VERSION "teryx"

NS_ :

BS_:

BU_: PI_DASH PICO_BOX SHINEGLE BENCH

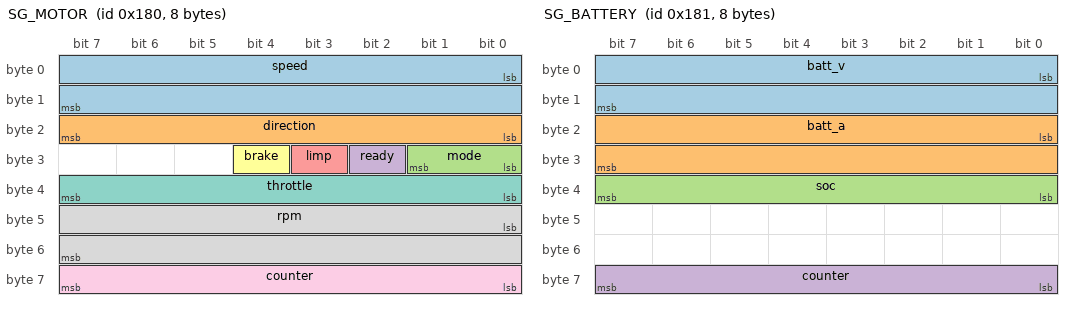
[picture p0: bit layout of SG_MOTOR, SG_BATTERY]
BO_ 384 SG_MOTOR: 8 SHINEGLE
 SG_ speed : 0|16@1+ (0.1,0) [0|6553.5] "km/h" Vector__XXX
 SG_ direction : 16|8@1+ (1,0) [0|255] "" Vector__XXX
 SG_ mode : 24|2@1+ (1,0) [0|3] "" Vector__XXX
 SG_ ready : 26|1@1+ (1,0) [0|1] "" Vector__XXX
 SG_ limp : 27|1@1+ (1,0) [0|1] "" Vector__XXX
 SG_ brake : 28|1@1+ (1,0) [0|1] "" Vector__XXX
 SG_ throttle : 32|8@1+ (1,0) [0|255] "%" Vector__XXX
 SG_ rpm : 40|16@1- (1,0) [-32768|32767] "rpm" Vector__XXX
 SG_ counter : 56|8@1+ (1,0) [0|255] "" Vector__XXX

BO_ 385 SG_BATTERY: 8 SHINEGLE
 SG_ batt_v : 0|16@1+ (0.1,0) [0|6553.5] "V" Vector__XXX
 SG_ batt_a : 16|16@1- (0.1,0) [-3276.8|3276.7] "A" Vector__XXX
 SG_ soc : 32|8@1+ (1,0) [0|255] "%" Vector__XXX
 SG_ counter : 56|8@1+ (1,0) [0|255] "" Vector__XXX

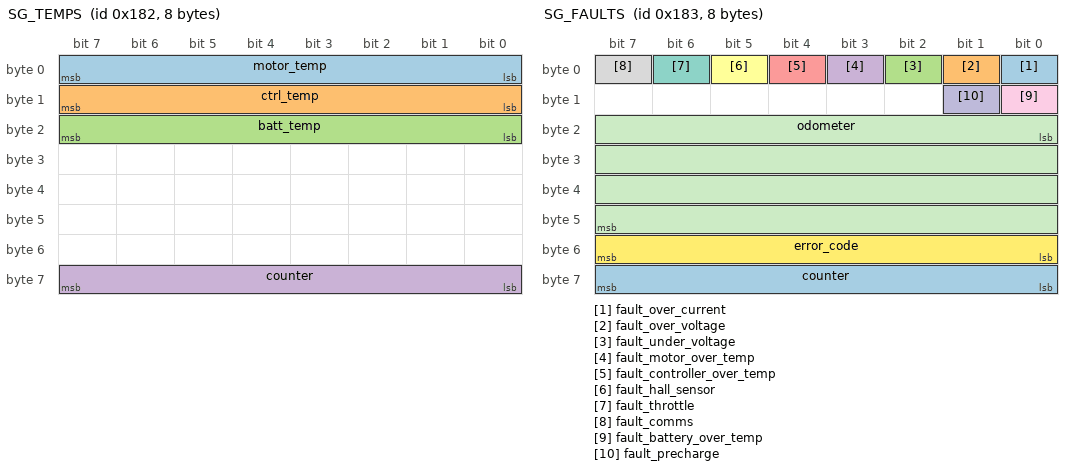
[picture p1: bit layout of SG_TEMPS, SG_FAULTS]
BO_ 386 SG_TEMPS: 8 SHINEGLE
 SG_ motor_temp : 0|8@1+ (1,-40) [-40|215] "C" Vector__XXX
 SG_ ctrl_temp : 8|8@1+ (1,-40) [-40|215] "C" Vector__XXX
 SG_ batt_temp : 16|8@1+ (1,-40) [-40|215] "C" Vector__XXX
 SG_ counter : 56|8@1+ (1,0) [0|255] "" Vector__XXX

BO_ 387 SG_FAULTS: 8 SHINEGLE
 SG_ fault_over_current : 0|1@1+ (1,0) [0|1] "" Vector__XXX
 SG_ fault_over_voltage : 1|1@1+ (1,0) [0|1] "" Vector__XXX
 SG_ fault_under_voltage : 2|1@1+ (1,0) [0|1] "" Vector__XXX
 SG_ fault_motor_over_temp : 3|1@1+ (1,0) [0|1] "" Vector__XXX
 SG_ fault_controller_over_temp : 4|1@1+ (1,0) [0|1] "" Vector__XXX
 SG_ fault_hall_sensor : 5|1@1+ (1,0) [0|1] "" Vector__XXX
 SG_ fault_throttle : 6|1@1+ (1,0) [0|1] "" Vector__XXX
 SG_ fault_comms : 7|1@1+ (1,0) [0|1] "" Vector__XXX
 SG_ fault_battery_over_temp : 8|1@1+ (1,0) [0|1] "" Vector__XXX
 SG_ fault_precharge : 9|1@1+ (1,0) [0|1] "" Vector__XXX
 SG_ odometer : 16|32@1+ (0.1,0) [0|4.29497e+08] "km" Vector__XXX
 SG_ error_code : 48|8@1+ (1,0) [0|255] "" Vector__XXX
 SG_ counter : 56|8@1+ (1,0) [0|255] "" Vector__XXX

BO_ 1792 PI_HEARTBEAT: 8 PI_DASH
 SG_ counter : 0|8@1+ (1,0) [0|255] "" Vector__XXX
 SG_ dash_state : 8|8@1+ (1,0) [0|255] "" Vector__XXX

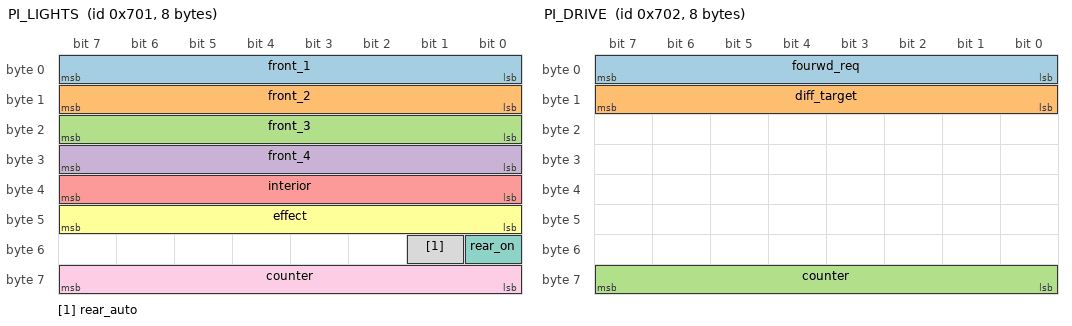
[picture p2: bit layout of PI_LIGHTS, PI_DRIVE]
BO_ 1793 PI_LIGHTS: 8 PI_DASH
 SG_ front_1 : 0|8@1+ (1,0) [0|255] "" Vector__XXX
 SG_ front_2 : 8|8@1+ (1,0) [0|255] "" Vector__XXX
 SG_ front_3 : 16|8@1+ (1,0) [0|255] "" Vector__XXX
 SG_ front_4 : 24|8@1+ (1,0) [0|255] "" Vector__XXX
 SG_ interior : 32|8@1+ (1,0) [0|255] "" Vector__XXX
 SG_ effect : 40|8@1+ (1,0) [0|255] "" Vector__XXX
 SG_ rear_on : 48|1@1+ (1,0) [0|1] "" Vector__XXX
 SG_ rear_auto : 49|1@1+ (1,0) [0|1] "" Vector__XXX
 SG_ counter : 56|8@1+ (1,0) [0|255] "" Vector__XXX

BO_ 1794 PI_DRIVE: 8 PI_DASH
 SG_ fourwd_req : 0|8@1+ (1,0) [0|255] "" Vector__XXX
 SG_ diff_target : 8|8@1+ (1,0) [0|255] "%" Vector__XXX
 SG_ counter : 56|8@1+ (1,0) [0|255] "" Vector__XXX

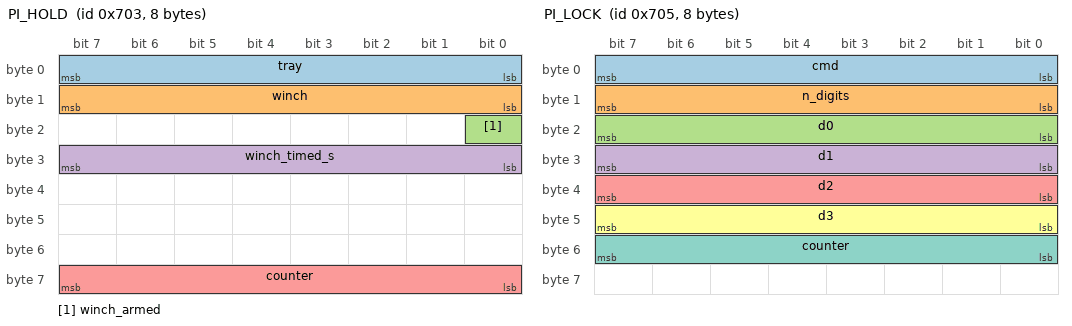
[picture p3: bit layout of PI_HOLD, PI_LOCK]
BO_ 1795 PI_HOLD: 8 PI_DASH
 SG_ tray : 0|8@1- (1,0) [-128|127] "" Vector__XXX
 SG_ winch : 8|8@1- (1,0) [-128|127] "" Vector__XXX
 SG_ winch_armed : 16|1@1+ (1,0) [0|1] "" Vector__XXX
 SG_ winch_timed_s : 24|8@1+ (1,0) [0|255] "s" Vector__XXX
 SG_ counter : 56|8@1+ (1,0) [0|255] "" Vector__XXX

BO_ 1796 PI_SETTINGS: 8 PI_DASH
 SG_ key : 0|8@1+ (1,0) [0|255] "" Vector__XXX
 SG_ value : 16|16@1+ (1,0) [0|65535] "" Vector__XXX

BO_ 1797 PI_LOCK: 8 PI_DASH
 SG_ cmd : 0|8@1+ (1,0) [0|255] "" Vector__XXX
 SG_ n_digits : 8|8@1+ (1,0) [0|255] "" Vector__XXX
 SG_ d0 : 16|8@1+ (1,0) [0|255] "" Vector__XXX
 SG_ d1 : 24|8@1+ (1,0) [0|255] "" Vector__XXX
 SG_ d2 : 32|8@1+ (1,0) [0|255] "" Vector__XXX
 SG_ d3 : 40|8@1+ (1,0) [0|255] "" Vector__XXX
 SG_ counter : 48|8@1+ (1,0) [0|255] "" Vector__XXX

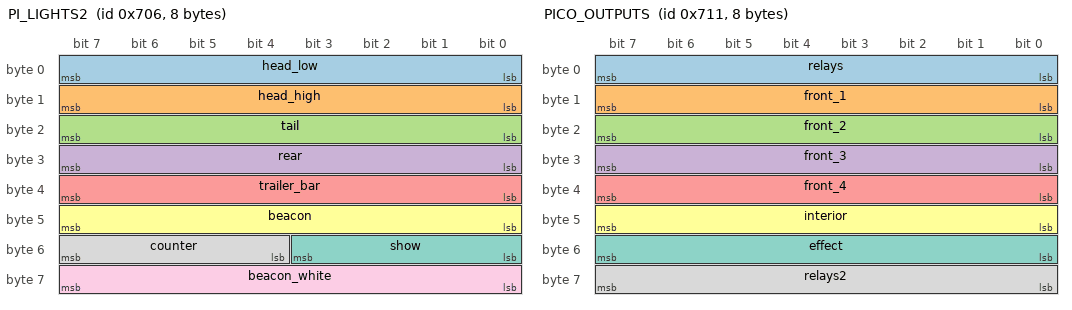
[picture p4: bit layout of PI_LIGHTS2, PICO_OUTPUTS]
BO_ 1798 PI_LIGHTS2: 8 PI_DASH
 SG_ head_low : 0|8@1+ (1,0) [0|255] "" Vector__XXX
 SG_ head_high : 8|8@1+ (1,0) [0|255] "" Vector__XXX
 SG_ tail : 16|8@1+ (1,0) [0|255] "" Vector__XXX
 SG_ rear : 24|8@1+ (1,0) [0|255] "" Vector__XXX
 SG_ trailer_bar : 32|8@1+ (1,0) [0|255] "" Vector__XXX
 SG_ beacon : 40|8@1+ (1,0) [0|255] "" Vector__XXX
 SG_ show : 48|4@1+ (1,0) [0|15] "" Vector__XXX
 SG_ counter : 52|4@1+ (1,0) [0|15] "" Vector__XXX
 SG_ beacon_white : 56|8@1+ (1,0) [0|255] "" Vector__XXX

BO_ 1823 PI_FW_UPDATE: 8 PI_DASH
 SG_ magic : 0|16@1+ (1,0) [0|65535] "" Vector__XXX

BO_ 1808 PICO_STATUS: 8 PICO_BOX
 SG_ counter : 0|8@1+ (1,0) [0|255] "" Vector__XXX
 SG_ fault_bits : 8|16@1+ (1,0) [0|65535] "" Vector__XXX
 SG_ inputs : 24|8@1+ (1,0) [0|255] "" Vector__XXX
 SG_ state : 32|2@1+ (1,0) [0|3] "" Vector__XXX
 SG_ on_defaults : 35|1@1+ (1,0) [0|1] "" Vector__XXX
 SG_ fourwd_wait : 36|1@1+ (1,0) [0|1] "" Vector__XXX
 SG_ diff_wait : 37|1@1+ (1,0) [0|1] "" Vector__XXX
 SG_ throttle_hold : 38|1@1+ (1,0) [0|1] "" Vector__XXX
 SG_ reject_reason : 40|4@1+ (1,0) [0|15] "" Vector__XXX
 SG_ reject_count : 44|4@1+ (1,0) [0|15] "" Vector__XXX
 SG_ winch_armed : 48|1@1+ (1,0) [0|1] "" Vector__XXX
 SG_ speed_valid : 49|1@1+ (1,0) [0|1] "" Vector__XXX
 SG_ reverse_active : 50|1@1+ (1,0) [0|1] "" Vector__XXX
 SG_ shutdown_request : 51|1@1+ (1,0) [0|1] "" Vector__XXX
 SG_ parked : 52|1@1+ (1,0) [0|1] "" Vector__XXX
 SG_ sentry_hold : 53|1@1+ (1,0) [0|1] "" Vector__XXX
 SG_ sentry_flat : 54|1@1+ (1,0) [0|1] "" Vector__XXX
 SG_ speed : 56|8@1+ (1,0) [0|255] "km/h" Vector__XXX

BO_ 1809 PICO_OUTPUTS: 8 PICO_BOX
 SG_ relays : 0|8@1+ (1,0) [0|255] "" Vector__XXX
 SG_ front_1 : 8|8@1+ (1,0) [0|255] "" Vector__XXX
 SG_ front_2 : 16|8@1+ (1,0) [0|255] "" Vector__XXX
 SG_ front_3 : 24|8@1+ (1,0) [0|255] "" Vector__XXX
 SG_ front_4 : 32|8@1+ (1,0) [0|255] "" Vector__XXX
 SG_ interior : 40|8@1+ (1,0) [0|255] "" Vector__XXX
 SG_ effect : 48|8@1+ (1,0) [0|255] "" Vector__XXX
 SG_ relays2 : 56|8@1+ (1,0) [0|255] "" Vector__XXX

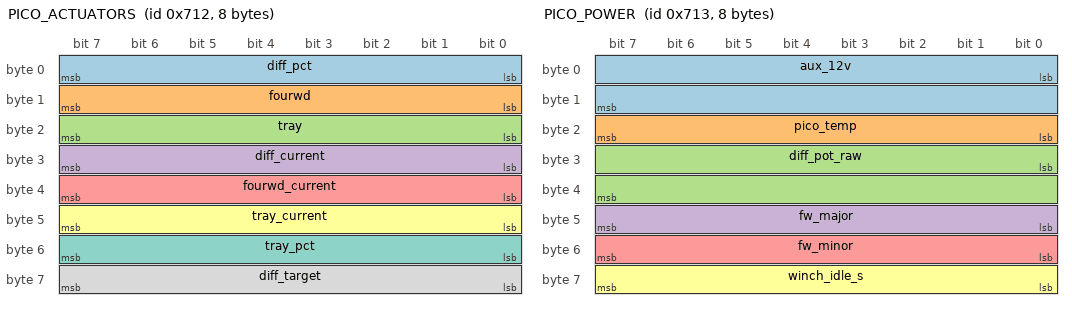
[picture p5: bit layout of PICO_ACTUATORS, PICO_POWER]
BO_ 1810 PICO_ACTUATORS: 8 PICO_BOX
 SG_ diff_pct : 0|8@1+ (1,0) [0|255] "%" Vector__XXX
 SG_ fourwd : 8|8@1+ (1,0) [0|255] "" Vector__XXX
 SG_ tray : 16|8@1+ (1,0) [0|255] "" Vector__XXX
 SG_ diff_current : 24|8@1+ (0.1,0) [0|25.5] "A" Vector__XXX
 SG_ fourwd_current : 32|8@1+ (0.1,0) [0|25.5] "A" Vector__XXX
 SG_ tray_current : 40|8@1+ (0.1,0) [0|25.5] "A" Vector__XXX
 SG_ tray_pct : 48|8@1+ (1,0) [0|255] "%" Vector__XXX
 SG_ diff_target : 56|8@1+ (1,0) [0|255] "%" Vector__XXX

BO_ 1811 PICO_POWER: 8 PICO_BOX
 SG_ aux_12v : 0|16@1+ (0.001,0) [0|65.535] "V" Vector__XXX
 SG_ pico_temp : 16|8@1- (1,0) [-128|127] "C" Vector__XXX
 SG_ diff_pot_raw : 24|16@1+ (1,0) [0|65535] "" Vector__XXX
 SG_ fw_major : 40|8@1+ (1,0) [0|255] "" Vector__XXX
 SG_ fw_minor : 48|8@1+ (1,0) [0|255] "" Vector__XXX
 SG_ winch_idle_s : 56|8@1+ (1,0) [0|255] "s" Vector__XXX

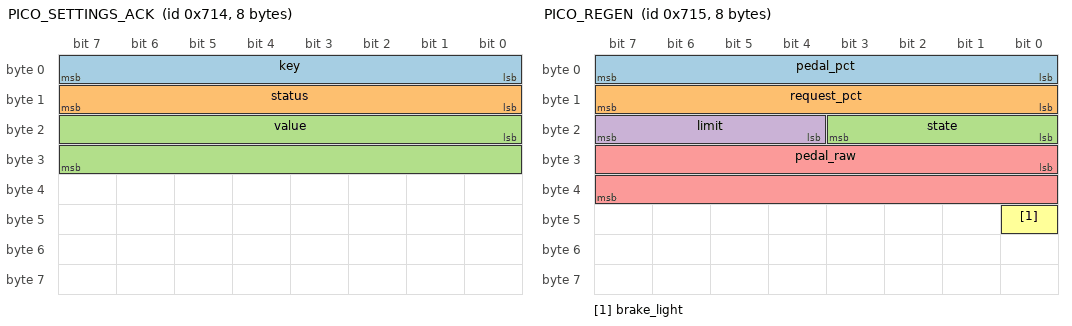
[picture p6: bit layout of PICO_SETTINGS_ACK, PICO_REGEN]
BO_ 1812 PICO_SETTINGS_ACK: 8 PICO_BOX
 SG_ key : 0|8@1+ (1,0) [0|255] "" Vector__XXX
 SG_ status : 8|8@1+ (1,0) [0|255] "" Vector__XXX
 SG_ value : 16|16@1+ (1,0) [0|65535] "" Vector__XXX

BO_ 1813 PICO_REGEN: 8 PICO_BOX
 SG_ pedal_pct : 0|8@1+ (1,0) [0|255] "%" Vector__XXX
 SG_ request_pct : 8|8@1+ (1,0) [0|255] "%" Vector__XXX
 SG_ state : 16|4@1+ (1,0) [0|15] "" Vector__XXX
 SG_ limit : 20|4@1+ (1,0) [0|15] "" Vector__XXX
 SG_ pedal_raw : 24|16@1+ (1,0) [0|65535] "" Vector__XXX
 SG_ brake_light : 40|1@1+ (1,0) [0|1] "" Vector__XXX

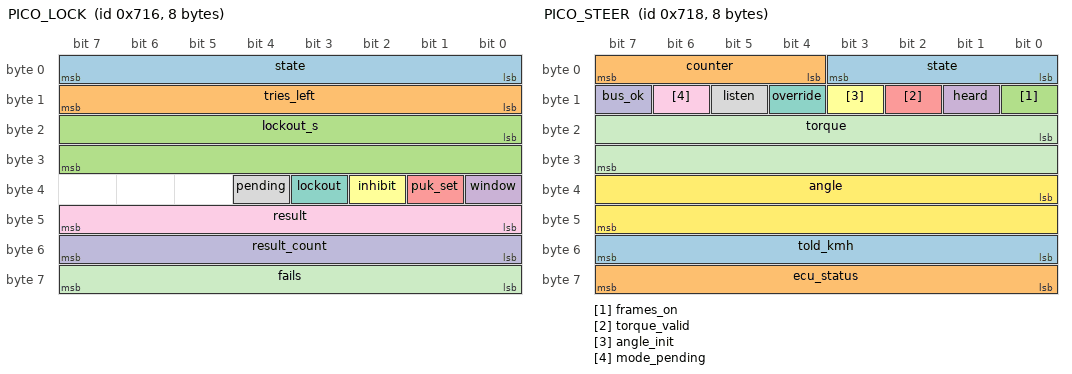
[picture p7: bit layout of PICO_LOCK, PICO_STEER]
BO_ 1814 PICO_LOCK: 8 PICO_BOX
 SG_ state : 0|8@1+ (1,0) [0|255] "" Vector__XXX
 SG_ tries_left : 8|8@1+ (1,0) [0|255] "" Vector__XXX
 SG_ lockout_s : 16|16@1+ (1,0) [0|65535] "s" Vector__XXX
 SG_ window : 32|1@1+ (1,0) [0|1] "" Vector__XXX
 SG_ puk_set : 33|1@1+ (1,0) [0|1] "" Vector__XXX
 SG_ inhibit : 34|1@1+ (1,0) [0|1] "" Vector__XXX
 SG_ lockout : 35|1@1+ (1,0) [0|1] "" Vector__XXX
 SG_ pending : 36|1@1+ (1,0) [0|1] "" Vector__XXX
 SG_ result : 40|8@1+ (1,0) [0|255] "" Vector__XXX
 SG_ result_count : 48|8@1+ (1,0) [0|255] "" Vector__XXX
 SG_ fails : 56|8@1+ (1,0) [0|255] "" Vector__XXX

BO_ 1815 PICO_LIGHTS2: 8 PICO_BOX
 SG_ head_l_low : 0|4@1+ (1,0) [0|15] "" Vector__XXX
 SG_ head_l_high : 4|4@1+ (1,0) [0|15] "" Vector__XXX
 SG_ head_r_low : 8|4@1+ (1,0) [0|15] "" Vector__XXX
 SG_ head_r_high : 12|4@1+ (1,0) [0|15] "" Vector__XXX
 SG_ tail_l : 16|4@1+ (1,0) [0|15] "" Vector__XXX
 SG_ brake_l : 20|4@1+ (1,0) [0|15] "" Vector__XXX
 SG_ tail_r : 24|4@1+ (1,0) [0|15] "" Vector__XXX
 SG_ brake_r : 28|4@1+ (1,0) [0|15] "" Vector__XXX
 SG_ trailer_tail : 32|4@1+ (1,0) [0|15] "" Vector__XXX
 SG_ trailer_stop : 36|4@1+ (1,0) [0|15] "" Vector__XXX
 SG_ flood_l : 40|4@1+ (1,0) [0|15] "" Vector__XXX
 SG_ flood_r : 44|4@1+ (1,0) [0|15] "" Vector__XXX
 SG_ beacon : 48|4@1+ (1,0) [0|15] "" Vector__XXX
 SG_ trailer_bar : 52|4@1+ (1,0) [0|15] "" Vector__XXX
 SG_ beacon_white : 56|4@1+ (1,0) [0|15] "" Vector__XXX
 SG_ show_running : 60|1@1+ (1,0) [0|1] "" Vector__XXX
 SG_ show_blocked : 61|1@1+ (1,0) [0|1] "" Vector__XXX
 SG_ pwm_ok : 62|1@1+ (1,0) [0|1] "" Vector__XXX

BO_ 1816 PICO_STEER: 8 PICO_BOX
 SG_ state : 0|4@1+ (1,0) [0|15] "" Vector__XXX
 SG_ counter : 4|4@1+ (1,0) [0|15] "" Vector__XXX
 SG_ frames_on : 8|1@1+ (1,0) [0|1] "" Vector__XXX
 SG_ heard : 9|1@1+ (1,0) [0|1] "" Vector__XXX
 SG_ torque_valid : 10|1@1+ (1,0) [0|1] "" Vector__XXX
 SG_ angle_init : 11|1@1+ (1,0) [0|1] "" Vector__XXX
 SG_ override : 12|1@1+ (1,0) [0|1] "" Vector__XXX
 SG_ listen : 13|1@1+ (1,0) [0|1] "" Vector__XXX
 SG_ mode_pending : 14|1@1+ (1,0) [0|1] "" Vector__XXX
 SG_ bus_ok : 15|1@1+ (1,0) [0|1] "" Vector__XXX
 SG_ torque : 16|16@1- (1,0) [-32768|32767] "" Vector__XXX
 SG_ angle : 32|16@1- (0.1,0) [-3276.8|3276.7] "deg" Vector__XXX
 SG_ told_kmh : 48|8@1+ (1,0) [0|255] "km/h" Vector__XXX
 SG_ ecu_status : 56|8@1+ (1,0) [0|255] "" Vector__XXX

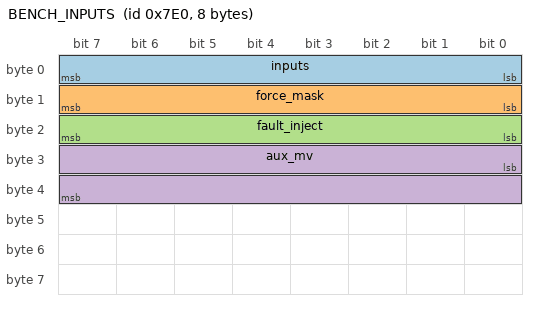
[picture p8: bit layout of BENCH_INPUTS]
BO_ 2016 BENCH_INPUTS: 8 BENCH
 SG_ inputs : 0|8@1+ (1,0) [0|255] "" Vector__XXX
 SG_ force_mask : 8|8@1+ (1,0) [0|255] "" Vector__XXX
 SG_ fault_inject : 16|8@1+ (1,0) [0|255] "" Vector__XXX
 SG_ aux_mv : 24|16@1+ (1,0) [0|65535] "mV" Vector__XXX

CM_ BO_ 384 "PLACEHOLDER layout. Bytes 0-2 are what the Pico reads for its speed interlocks.";
CM_ SG_ 385 batt_a "+ = draw, - = regen";
CM_ BO_ 385 "PLACEHOLDER layout.";
CM_ BO_ 386 "PLACEHOLDER layout.";
CM_ SG_ 387 fault_over_current "Motor over current";
CM_ SG_ 387 fault_over_voltage "Battery voltage too high";
CM_ SG_ 387 fault_under_voltage "Battery voltage too low";
CM_ SG_ 387 fault_motor_over_temp "Motor too hot";
CM_ SG_ 387 fault_controller_over_temp "Controller too hot";
CM_ SG_ 387 fault_hall_sensor "Motor position sensor fault";
CM_ SG_ 387 fault_throttle "Throttle fault";
CM_ SG_ 387 fault_comms "Controller comms fault";
CM_ SG_ 387 fault_battery_over_temp "Battery too hot";
CM_ SG_ 387 fault_precharge "Precharge fault";
CM_ SG_ 387 error_code "Controller ErrorCode, same number as the LED flash count (0 or 1 = no fault). Text in config/shinegle-faults.yaml";
CM_ BO_ 387 "PLACEHOLDER layout.";
CM_ BO_ 1792 "Pico stops tray, winch and actuators if this goes quiet for 500 ms.";
CM_ SG_ 1793 rear_auto "Rear pods on automatically in reverse";
CM_ BO_ 1793 "On change, plus a resend every 1 s. Brightness 0-255 (0 = off). On/off-only bars treat anything above 0 as on.";
CM_ SG_ 1794 fourwd_req "0 = 2WD, 1 = 4WD";
CM_ BO_ 1794 "On change, plus a resend every 1 s.";
CM_ SG_ 1795 tray "-1 down, 0 stop, +1 up";
CM_ SG_ 1795 winch "-1 out, 0 stop, +1 in";
CM_ SG_ 1795 winch_timed_s "Timed pull length, 0 = plain hold. Pico stops it on time by itself, capped at setting 21";
CM_ BO_ 1795 "Hold-to-run, sent at 10 Hz only while a button is held. Pico stops if it goes quiet for 300 ms.";
CM_ BO_ 1796 "On change, one key per frame. The Pico echoes it on 0x714 as an ack. Keys are in SETTINGS below. 0xF0 = save to flash, 0xF1 = reset defaults.";
CM_ BO_ 1797 "Vehicle lock command, on demand (docs/vehicle-lock.md). Digits are BCD, first digit in the high nibble of d0. PIN 4-6 digits, recovery code 8. The Pico keeps only a salted hash and answers on 0x716 straight away.";
CM_ SG_ 1798 head_low "Low beam, both sides";
CM_ SG_ 1798 head_high "High beam, both sides. Wins over low";
CM_ SG_ 1798 tail "Tail lights, 0 = automatic (on with any headlight or front bar)";
CM_ SG_ 1798 rear "Rear flood level while 0x701 rear_on is set, 0 = full";
CM_ SG_ 1798 beacon "Roof beacon brightness, 0 = off. The Pico flashes it at 3 Hz";
CM_ SG_ 1798 show "Light show, parked only";
CM_ SG_ 1798 beacon_white "White side of the beacon, 0 = off. 3 Hz opposite the amber, only when stopped";
CM_ BO_ 1798 "Stock lamps, rear floods, beacon, trailer bar and the light show (docs/lights.md). On change, plus a resend every 1 s. Levels 0-255, 0 = off. The Pico keeps brake lights at full, never dims headlights or tails while moving, and only runs a show when parked.";
CM_ BO_ 1823 "Pico reboots to its bootloader when magic = 0x5445 ('TE') and parked.";
CM_ SG_ 1808 fault_bits "See FAULT_BITS";
CM_ SG_ 1808 inputs "MCP23017 B0-B7, see INPUT_BITS";
CM_ SG_ 1808 on_defaults "Pico is running on default settings, please resend";
CM_ SG_ 1808 fourwd_wait "A 2WD/4WD request is waiting for the right speed (docs/drive-changes.md)";
CM_ SG_ 1808 diff_wait "A diff lock request is waiting for the right speed";
CM_ SG_ 1808 throttle_hold "Throttle held: a shift is running from a standstill";
CM_ SG_ 1808 reject_reason "Why the last request was refused";
CM_ SG_ 1808 reject_count "Goes up by one each time a request is refused";
CM_ SG_ 1808 shutdown_request "Key off: Pi should shut down";
CM_ SG_ 1808 parked "Stopped and safe for OTA updates";
CM_ SG_ 1808 sentry_hold "Key off, power kept on because the Pi asked for sentry";
CM_ SG_ 1808 sentry_flat "Sentry refused: 12V under setting 32 (until the key goes on)";
CM_ SG_ 1808 speed "Speed as the Pico sees it, 255 = unknown";
CM_ SG_ 1809 relays "See RELAY_BITS";
CM_ SG_ 1809 relays2 "Second relay board, see RELAY2_BITS (power steering on, drive lock)";
CM_ BO_ 1809 "What the outputs are actually doing (after effects and safety).";
CM_ SG_ 1810 diff_pct "From the actuator pot";
CM_ SG_ 1810 tray_pct "Estimate from run time, no pot on the tray";
CM_ SG_ 1810 diff_target "While diff_wait is set, the % it's waiting to move to";
CM_ SG_ 1811 diff_pot_raw "Raw ADS1115 reading, for calibrating keys 14/15";
CM_ SG_ 1811 winch_idle_s "Seconds since the winch last ran while armed (caps at 255)";
CM_ BO_ 1812 "Echo of each 0x704 frame once the Pico has applied it (value is what it actually used).";
CM_ SG_ 1813 pedal_pct "Brake pedal travel from the pedal sensor";
CM_ SG_ 1813 request_pct "Regen asked of the Shinegle, after every limit";
CM_ SG_ 1813 limit "What is holding regen back, if anything";
CM_ SG_ 1813 pedal_raw "Raw ADS1115 reading, for calibrating keys 28/29";
CM_ SG_ 1813 brake_light "Regen is strong enough to light the brake lights";
CM_ BO_ 1813 "Brake pedal regen (docs/brake-regen.md). All zero with state off while the feature is off.";
CM_ SG_ 1814 tries_left "Wrong tries left before a lockout";
CM_ SG_ 1814 lockout_s "Lockout time left";
CM_ SG_ 1814 window "Change window open (PIN checked in the last 60 s)";
CM_ SG_ 1814 puk_set "A recovery code is stored";
CM_ SG_ 1814 inhibit "Drive inhibit asked for (how is TBC until the Shinegle is decoded)";
CM_ SG_ 1814 pending "Remote lock asked for, waiting until stopped 10 s or key off";
CM_ SG_ 1814 result "Result of the last 0x705";
CM_ SG_ 1814 result_count "Goes up by one per 0x705";
CM_ SG_ 1814 fails "Wrong tries in a row (kept over power cuts)";
CM_ BO_ 1814 "Vehicle lock state (docs/vehicle-lock.md). Also sent straight after every 0x705.";
CM_ SG_ 1815 show_blocked "A show was asked for but the Teryx isn't parked (key on, park brake, stopped)";
CM_ SG_ 1815 pwm_ok "PCA9685 answering";
CM_ BO_ 1815 "What the PCA9685 lamps are actually doing, after every safety rule (docs/lights.md). Levels are 0-15 (top 4 bits of 0-255).";
CM_ SG_ 1816 frames_on "Speed frames going to the ECU";
CM_ SG_ 1816 heard "Something heard from the ECU lately";
CM_ SG_ 1816 torque_valid "0x260 fresh: torque and angle are real";
CM_ SG_ 1816 angle_init "ECU says the angle is still initialising";
CM_ SG_ 1816 override "ECU says the driver is turning hard";
CM_ SG_ 1816 listen "Setting 37 on: a quiet ECU is a warning";
CM_ SG_ 1816 mode_pending "Steering mode change waiting for the Teryx to stop";
CM_ SG_ 1816 bus_ok "Steering CAN board working";
CM_ SG_ 1816 torque "Driver torque, raw from the ECU (units unknown)";
CM_ SG_ 1816 angle "Steering angle from the ECU";
CM_ SG_ 1816 told_kmh "Speed told to the ECU, 255 = no frames";
CM_ SG_ 1816 ecu_status "EPS_STATUS LKA_STATE byte, 255 = never heard";
CM_ BO_ 1816 "Power steering (docs/power-steering-aqua.md). Torque, angle and ECU status are only real once the Aqua ECU has been heard (flag torque_valid).";
CM_ SG_ 2016 inputs "Bits as INPUT_BITS";
CM_ SG_ 2016 force_mask "Which input bits to force";
CM_ SG_ 2016 fault_inject "See BENCH_FAULTS";
CM_ SG_ 2016 aux_mv "Fake 12V reading, 0 = leave alone";
CM_ BO_ 2016 "HOST/BENCH BUILD ONLY. Lets the simulator drive the Pico's wired inputs and inject faults. The real Pico firmware ignores it.";

BA_DEF_ BO_ "GenMsgCycleTime" INT 0 65535;
BA_DEF_DEF_ "GenMsgCycleTime" 0;
BA_ "GenMsgCycleTime" BO_ 384 50;
BA_ "GenMsgCycleTime" BO_ 385 100;
BA_ "GenMsgCycleTime" BO_ 386 500;
BA_ "GenMsgCycleTime" BO_ 387 200;
BA_ "GenMsgCycleTime" BO_ 1792 100;
BA_ "GenMsgCycleTime" BO_ 1793 1000;
BA_ "GenMsgCycleTime" BO_ 1794 1000;
BA_ "GenMsgCycleTime" BO_ 1795 100;
BA_ "GenMsgCycleTime" BO_ 1798 1000;
BA_ "GenMsgCycleTime" BO_ 1808 100;
BA_ "GenMsgCycleTime" BO_ 1809 100;
BA_ "GenMsgCycleTime" BO_ 1810 100;
BA_ "GenMsgCycleTime" BO_ 1811 1000;
BA_ "GenMsgCycleTime" BO_ 1813 100;
BA_ "GenMsgCycleTime" BO_ 1814 100;
BA_ "GenMsgCycleTime" BO_ 1815 100;
BA_ "GenMsgCycleTime" BO_ 1816 100;
BA_ "GenMsgCycleTime" BO_ 2016 100;

VAL_ 384 direction 0 "neutral" 1 "forward" 2 "reverse" ;
VAL_ 384 mode 0 "eco" 1 "normal" 2 "sport" ;
VAL_ 1792 dash_state 0 "boot" 1 "ok" 2 "shutting_down" 3 "sentry" ;
VAL_ 1793 effect 0 "none" 1 "strobe" 2 "chase" 3 "outside_only" 4 "inside_only" 5 "breathe" 6 "sos" ;
VAL_ 1797 cmd 1 "lock" 2 "unlock" 3 "verify" 4 "set_pin" 5 "set_puk" 6 "remove" 7 "remote" ;
VAL_ 1798 show 0 "none" 1 "wave" 2 "breathe" 3 "roar" 4 "party" ;
VAL_ 1808 state 0 "boot" 1 "ok" 2 "degraded" 3 "failsafe" ;
VAL_ 1808 reject_reason 0 "none" 1 "too_fast" 2 "not_stopped" 3 "speed_unknown" 4 "not_armed" 5 "interlock" 6 "actuator_fault" 7 "low_12v" 8 "dash_link" 9 "ignition_off" 10 "at_limit" 11 "not_parked" 12 "winch_remote" 13 "bad_frame" 14 "wait_timeout" 15 "busy" ;
VAL_ 1809 effect 0 "none" 1 "strobe" 2 "chase" 3 "outside_only" 4 "inside_only" 5 "breathe" 6 "sos" ;
VAL_ 1810 fourwd 0 "2wd" 1 "4wd" 2 "to_4wd" 3 "to_2wd" 4 "fault" 5 "unknown" ;
VAL_ 1810 tray 0 "down" 1 "up" 2 "mid" 3 "raising" 4 "lowering" 5 "fault" ;
VAL_ 1812 status 0 "ok" 1 "unknown_key" 2 "out_of_range" 3 "locked" ;
VAL_ 1813 state 0 "off" 1 "ready" 2 "active" 3 "limited" 4 "sensor_fault" ;
VAL_ 1813 limit 0 "none" 1 "low_speed" 2 "speed_unknown" 3 "not_forward" 4 "battery_full" 5 "two_wd" 6 "sensor" 7 "throttle" ;
VAL_ 1814 state 0 "off" 1 "unlocked" 2 "locked" ;
VAL_ 1814 result 0 "none" 1 "ok" 2 "wrong" 3 "not_parked" 4 "no_pin" 5 "lockout" 6 "bad_digits" 7 "not_allowed" 8 "recovered" 9 "pending" ;
VAL_ 1816 state 0 "off" 1 "waking" 2 "ok" 3 "limp" 4 "manual" 5 "no_reply" 6 "ecu_fault" 7 "bus_error" ;
